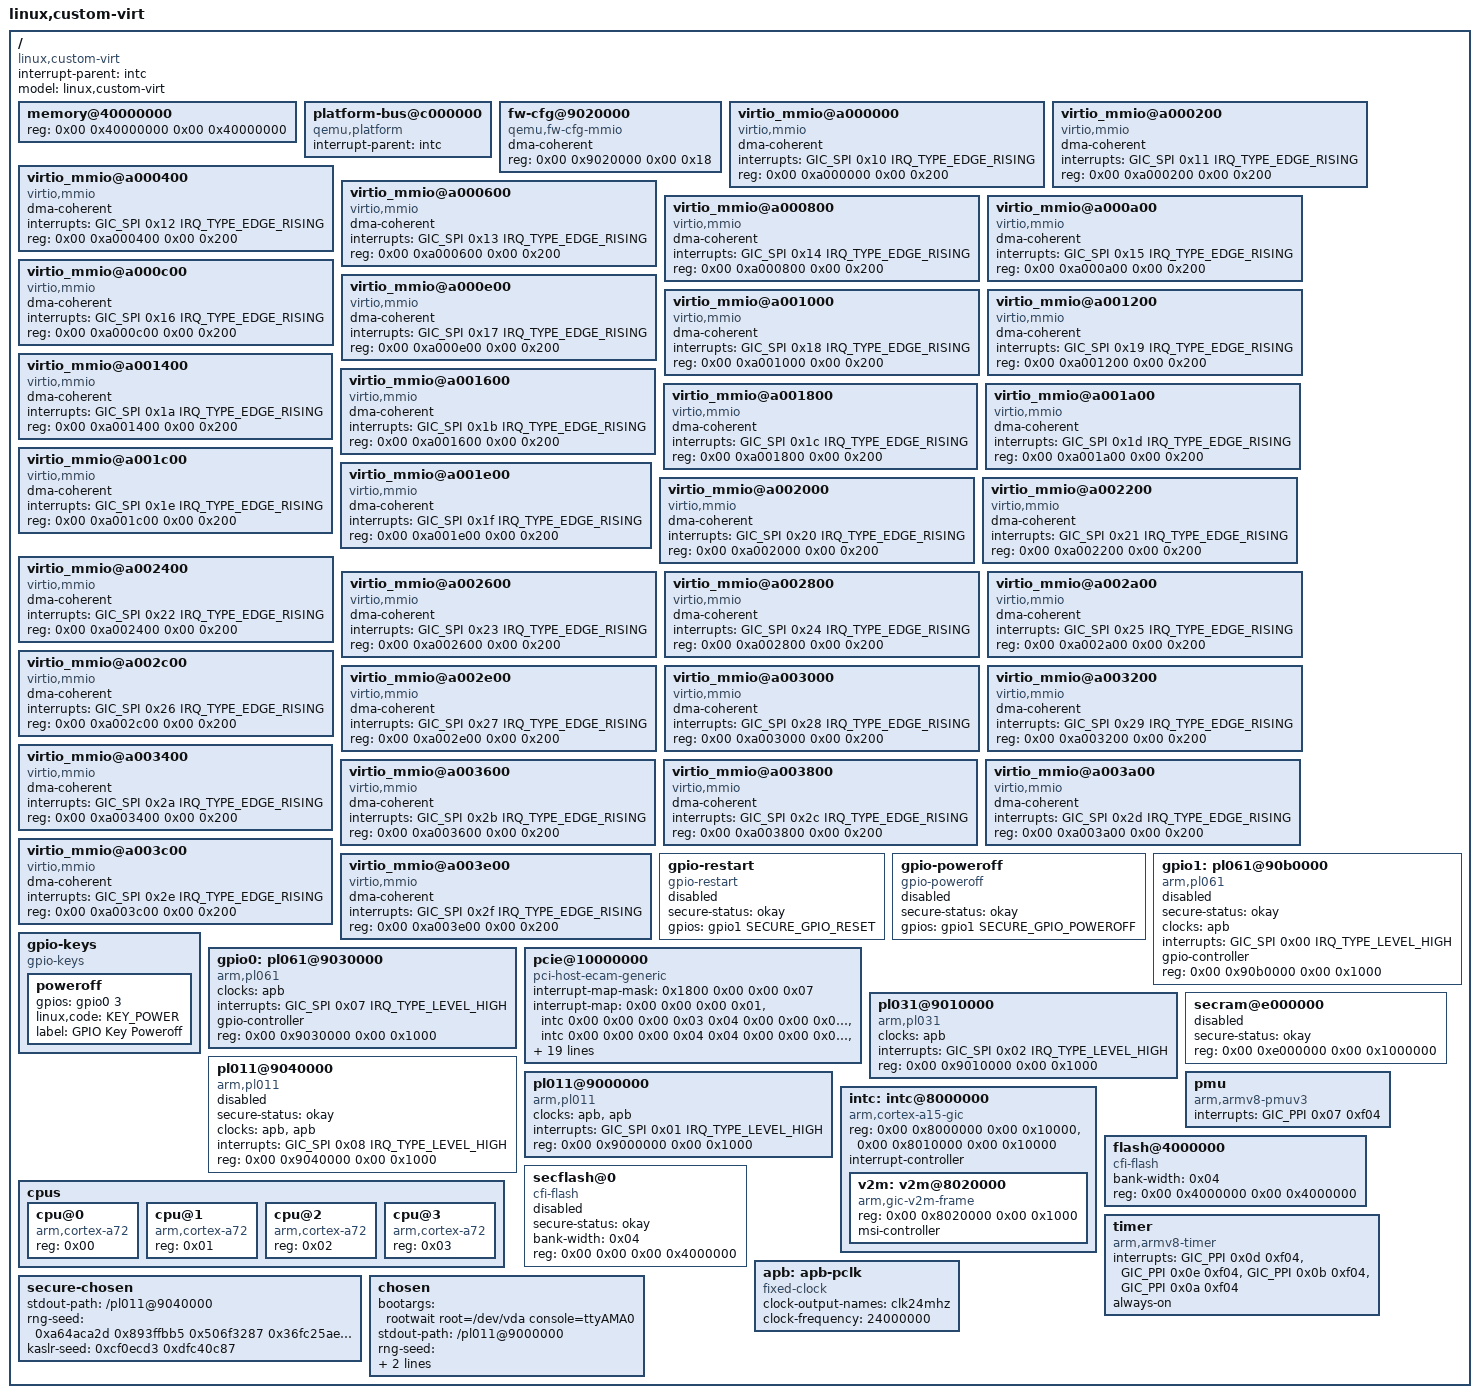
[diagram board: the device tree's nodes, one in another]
// SPDX-License-Identifier: GPL-2.0+
/dts-v1/;

#define SECURE_GPIO_POWEROFF 0
#define SECURE_GPIO_RESET    1

#define FDT_PCI_RANGE_RELOCATABLE          0x80000000
#define FDT_PCI_RANGE_PREFETCHABLE         0x40000000
#define FDT_PCI_RANGE_ALIASED              0x20000000
#define FDT_PCI_RANGE_TYPE_MASK            0x03000000
#define FDT_PCI_RANGE_MMIO_64BIT           0x03000000
#define FDT_PCI_RANGE_MMIO                 0x02000000
#define FDT_PCI_RANGE_IOPORT               0x01000000
#define FDT_PCI_RANGE_CONFIG               0x00000000

#include <dt-bindings/interrupt-controller/arm-gic.h>
#include <dt-bindings/input/linux-event-codes.h>

/ {
	interrupt-parent = <&intc>;
	model = "linux,custom-virt";
	#size-cells = <0x02>;
	#address-cells = <0x02>;
	compatible = "linux,custom-virt";

	memory@40000000 {
		reg = <0x00 0x40000000 0x00 0x40000000>;
		device_type = "memory";
	};

	platform-bus@c000000 {
		interrupt-parent = <&intc>;
		ranges = <0x00 0x00 0xc000000 0x2000000>;
		#address-cells = <0x01>;
		#size-cells = <0x01>;
		compatible = "qemu,platform", "simple-bus";
	};

	fw-cfg@9020000 {
		dma-coherent;
		reg = <0x00 0x9020000 0x00 0x18>;
		compatible = "qemu,fw-cfg-mmio";
	};

	virtio_mmio@a000000 {
		dma-coherent;
		interrupts = <GIC_SPI 0x10 IRQ_TYPE_EDGE_RISING>;
		reg = <0x00 0xa000000 0x00 0x200>;
		compatible = "virtio,mmio";
	};

	virtio_mmio@a000200 {
		dma-coherent;
		interrupts = <GIC_SPI 0x11 IRQ_TYPE_EDGE_RISING>;
		reg = <0x00 0xa000200 0x00 0x200>;
		compatible = "virtio,mmio";
	};

	virtio_mmio@a000400 {
		dma-coherent;
		interrupts = <GIC_SPI 0x12 IRQ_TYPE_EDGE_RISING>;
		reg = <0x00 0xa000400 0x00 0x200>;
		compatible = "virtio,mmio";
	};

	virtio_mmio@a000600 {
		dma-coherent;
		interrupts = <GIC_SPI 0x13 IRQ_TYPE_EDGE_RISING>;
		reg = <0x00 0xa000600 0x00 0x200>;
		compatible = "virtio,mmio";
	};

	virtio_mmio@a000800 {
		dma-coherent;
		interrupts = <GIC_SPI 0x14 IRQ_TYPE_EDGE_RISING>;
		reg = <0x00 0xa000800 0x00 0x200>;
		compatible = "virtio,mmio";
	};

	virtio_mmio@a000a00 {
		dma-coherent;
		interrupts = <GIC_SPI 0x15 IRQ_TYPE_EDGE_RISING>;
		reg = <0x00 0xa000a00 0x00 0x200>;
		compatible = "virtio,mmio";
	};

	virtio_mmio@a000c00 {
		dma-coherent;
		interrupts = <GIC_SPI 0x16 IRQ_TYPE_EDGE_RISING>;
		reg = <0x00 0xa000c00 0x00 0x200>;
		compatible = "virtio,mmio";
	};

	virtio_mmio@a000e00 {
		dma-coherent;
		interrupts = <GIC_SPI 0x17 IRQ_TYPE_EDGE_RISING>;
		reg = <0x00 0xa000e00 0x00 0x200>;
		compatible = "virtio,mmio";
	};

	virtio_mmio@a001000 {
		dma-coherent;
		interrupts = <GIC_SPI 0x18 IRQ_TYPE_EDGE_RISING>;
		reg = <0x00 0xa001000 0x00 0x200>;
		compatible = "virtio,mmio";
	};

	virtio_mmio@a001200 {
		dma-coherent;
		interrupts = <GIC_SPI 0x19 IRQ_TYPE_EDGE_RISING>;
		reg = <0x00 0xa001200 0x00 0x200>;
		compatible = "virtio,mmio";
	};

	virtio_mmio@a001400 {
		dma-coherent;
		interrupts = <GIC_SPI 0x1a IRQ_TYPE_EDGE_RISING>;
		reg = <0x00 0xa001400 0x00 0x200>;
		compatible = "virtio,mmio";
	};

	virtio_mmio@a001600 {
		dma-coherent;
		interrupts = <GIC_SPI 0x1b IRQ_TYPE_EDGE_RISING>;
		reg = <0x00 0xa001600 0x00 0x200>;
		compatible = "virtio,mmio";
	};

	virtio_mmio@a001800 {
		dma-coherent;
		interrupts = <GIC_SPI 0x1c IRQ_TYPE_EDGE_RISING>;
		reg = <0x00 0xa001800 0x00 0x200>;
		compatible = "virtio,mmio";
	};

	virtio_mmio@a001a00 {
		dma-coherent;
		interrupts = <GIC_SPI 0x1d IRQ_TYPE_EDGE_RISING>;
		reg = <0x00 0xa001a00 0x00 0x200>;
		compatible = "virtio,mmio";
	};

	virtio_mmio@a001c00 {
		dma-coherent;
		interrupts = <GIC_SPI 0x1e IRQ_TYPE_EDGE_RISING>;
		reg = <0x00 0xa001c00 0x00 0x200>;
		compatible = "virtio,mmio";
	};

	virtio_mmio@a001e00 {
		dma-coherent;
		interrupts = <GIC_SPI 0x1f IRQ_TYPE_EDGE_RISING>;
		reg = <0x00 0xa001e00 0x00 0x200>;
		compatible = "virtio,mmio";
	};

	virtio_mmio@a002000 {
		dma-coherent;
		interrupts = <GIC_SPI 0x20 IRQ_TYPE_EDGE_RISING>;
		reg = <0x00 0xa002000 0x00 0x200>;
		compatible = "virtio,mmio";
	};

	virtio_mmio@a002200 {
		dma-coherent;
		interrupts = <GIC_SPI 0x21 IRQ_TYPE_EDGE_RISING>;
		reg = <0x00 0xa002200 0x00 0x200>;
		compatible = "virtio,mmio";
	};

	virtio_mmio@a002400 {
		dma-coherent;
		interrupts = <GIC_SPI 0x22 IRQ_TYPE_EDGE_RISING>;
		reg = <0x00 0xa002400 0x00 0x200>;
		compatible = "virtio,mmio";
	};

	virtio_mmio@a002600 {
		dma-coherent;
		interrupts = <GIC_SPI 0x23 IRQ_TYPE_EDGE_RISING>;
		reg = <0x00 0xa002600 0x00 0x200>;
		compatible = "virtio,mmio";
	};

	virtio_mmio@a002800 {
		dma-coherent;
		interrupts = <GIC_SPI 0x24 IRQ_TYPE_EDGE_RISING>;
		reg = <0x00 0xa002800 0x00 0x200>;
		compatible = "virtio,mmio";
	};

	virtio_mmio@a002a00 {
		dma-coherent;
		interrupts = <GIC_SPI 0x25 IRQ_TYPE_EDGE_RISING>;
		reg = <0x00 0xa002a00 0x00 0x200>;
		compatible = "virtio,mmio";
	};

	virtio_mmio@a002c00 {
		dma-coherent;
		interrupts = <GIC_SPI 0x26 IRQ_TYPE_EDGE_RISING>;
		reg = <0x00 0xa002c00 0x00 0x200>;
		compatible = "virtio,mmio";
	};

	virtio_mmio@a002e00 {
		dma-coherent;
		interrupts = <GIC_SPI 0x27 IRQ_TYPE_EDGE_RISING>;
		reg = <0x00 0xa002e00 0x00 0x200>;
		compatible = "virtio,mmio";
	};

	virtio_mmio@a003000 {
		dma-coherent;
		interrupts = <GIC_SPI 0x28 IRQ_TYPE_EDGE_RISING>;
		reg = <0x00 0xa003000 0x00 0x200>;
		compatible = "virtio,mmio";
	};

	virtio_mmio@a003200 {
		dma-coherent;
		interrupts = <GIC_SPI 0x29 IRQ_TYPE_EDGE_RISING>;
		reg = <0x00 0xa003200 0x00 0x200>;
		compatible = "virtio,mmio";
	};

	virtio_mmio@a003400 {
		dma-coherent;
		interrupts = <GIC_SPI 0x2a IRQ_TYPE_EDGE_RISING>;
		reg = <0x00 0xa003400 0x00 0x200>;
		compatible = "virtio,mmio";
	};

	virtio_mmio@a003600 {
		dma-coherent;
		interrupts = <GIC_SPI 0x2b IRQ_TYPE_EDGE_RISING>;
		reg = <0x00 0xa003600 0x00 0x200>;
		compatible = "virtio,mmio";
	};

	virtio_mmio@a003800 {
		dma-coherent;
		interrupts = <GIC_SPI 0x2c IRQ_TYPE_EDGE_RISING>;
		reg = <0x00 0xa003800 0x00 0x200>;
		compatible = "virtio,mmio";
	};

	virtio_mmio@a003a00 {
		dma-coherent;
		interrupts = <GIC_SPI 0x2d IRQ_TYPE_EDGE_RISING>;
		reg = <0x00 0xa003a00 0x00 0x200>;
		compatible = "virtio,mmio";
	};

	virtio_mmio@a003c00 {
		dma-coherent;
		interrupts = <GIC_SPI 0x2e IRQ_TYPE_EDGE_RISING>;
		reg = <0x00 0xa003c00 0x00 0x200>;
		compatible = "virtio,mmio";
	};

	virtio_mmio@a003e00 {
		dma-coherent;
		interrupts = <GIC_SPI 0x2f IRQ_TYPE_EDGE_RISING>;
		reg = <0x00 0xa003e00 0x00 0x200>;
		compatible = "virtio,mmio";
	};

	gpio-restart {
		secure-status = "okay";
		status = "disabled";
		gpios = <&gpio1 SECURE_GPIO_RESET 0>;
		compatible = "gpio-restart";
	};

	gpio-poweroff {
		secure-status = "okay";
		status = "disabled";
		gpios = <&gpio1 SECURE_GPIO_POWEROFF 0>;
		compatible = "gpio-poweroff";
	};

	gpio1: pl061@90b0000 {
		secure-status = "okay";
		status = "disabled";
		clock-names = "apb_pclk";
		clocks = <&apb>;
		interrupts = <GIC_SPI 0x00 IRQ_TYPE_LEVEL_HIGH>;
		gpio-controller;
		#gpio-cells = <0x02>;
		compatible = "arm,pl061", "arm,primecell";
		reg = <0x00 0x90b0000 0x00 0x1000>;
	};

	gpio-keys {
		compatible = "gpio-keys";

		poweroff {
			gpios = <&gpio0 3 0>;
			linux,code = <KEY_POWER>;
			label = "GPIO Key Poweroff";
		};
	};

	gpio0: pl061@9030000 {
		clock-names = "apb_pclk";
		clocks = <&apb>;
		interrupts = <GIC_SPI 0x07 IRQ_TYPE_LEVEL_HIGH>;
		gpio-controller;
		#gpio-cells = <0x02>;
		compatible = "arm,pl061", "arm,primecell";
		reg = <0x00 0x9030000 0x00 0x1000>;
	};

	pcie@10000000 {
		interrupt-map-mask = <0x1800 0x00 0x00 0x07>;
		interrupt-map = <0x00 0x00 0x00 0x01 &intc 0x00 0x00 0x00 0x03 0x04 0x00 0x00 0x00 0x02 &intc 0x00 0x00 0x00 0x04 0x04 0x00 0x00 0x00 0x03 &intc 0x00 0x00 0x00 0x05 0x04 0x00 0x00 0x00 0x04 &intc 0x00 0x00 0x00 0x06 0x04 0x800 0x00 0x00 0x01 &intc 0x00 0x00 0x00 0x04 0x04 0x800 0x00 0x00 0x02 &intc 0x00 0x00 0x00 0x05 0x04 0x800 0x00 0x00 0x03 &intc 0x00 0x00 0x00 0x06 0x04 0x800 0x00 0x00 0x04 &intc 0x00 0x00 0x00 0x03 0x04 0x1000 0x00 0x00 0x01 &intc 0x00 0x00 0x00 0x05 0x04 0x1000 0x00 0x00 0x02 &intc 0x00 0x00 0x00 0x06 0x04 0x1000 0x00 0x00 0x03 &intc 0x00 0x00 0x00 0x03 0x04 0x1000 0x00 0x00 0x04 &intc 0x00 0x00 0x00 0x04 0x04 0x1800 0x00 0x00 0x01 &intc 0x00 0x00 0x00 0x06 0x04 0x1800 0x00 0x00 0x02 &intc 0x00 0x00 0x00 0x03 0x04 0x1800 0x00 0x00 0x03 &intc 0x00 0x00 0x00 0x04 0x04 0x1800 0x00 0x00 0x04 &intc 0x00 0x00 0x00 0x05 0x04>;
		#interrupt-cells = <0x01>;
		ranges =	<FDT_PCI_RANGE_IOPORT 0x00 0x00>, 
					<0x00 0x3eff0000 0x00 0x10000>, 
					<FDT_PCI_RANGE_MMIO 0x00 0x10000000>, 
					<0x00 0x10000000 0x00 0x2eff0000>, 
					<FDT_PCI_RANGE_MMIO_64BIT>, 
					<0x80 0x00>, 
					<0x80 0x00 0x80 0x00>;
		reg = <0x40 0x10000000 0x00 0x10000000>;
		msi-map = <0x00 0x8006 0x00 0x10000>;
		dma-coherent;
		bus-range = <0x00 0xff>;
		linux,pci-domain = <0x00>;
		#size-cells = <0x02>;
		#address-cells = <0x03>;
		device_type = "pci";
		compatible = "pci-host-ecam-generic";
	};

	pl031@9010000 {
		clock-names = "apb_pclk";
		clocks = <&apb>;
		interrupts = <GIC_SPI 0x02 IRQ_TYPE_LEVEL_HIGH>;
		reg = <0x00 0x9010000 0x00 0x1000>;
		compatible = "arm,pl031", "arm,primecell";
	};

	pl011@9040000 {
		secure-status = "okay";
		status = "disabled";
		clock-names = "uartclk", "apb_pclk";
		clocks = <&apb &apb>;
		interrupts = <GIC_SPI 0x08 IRQ_TYPE_LEVEL_HIGH>;
		reg = <0x00 0x9040000 0x00 0x1000>;
		compatible = "arm,pl011", "arm,primecell";
	};

	secram@e000000 {
		secure-status = "okay";
		status = "disabled";
		reg = <0x00 0xe000000 0x00 0x1000000>;
		device_type = "memory";
	};

	pl011@9000000 {
		clock-names = "uartclk", "apb_pclk";
		clocks = <&apb &apb>;
		interrupts = <GIC_SPI 0x01 IRQ_TYPE_LEVEL_HIGH>;
		reg = <0x00 0x9000000 0x00 0x1000>;
		compatible = "arm,pl011", "arm,primecell";
	};

	pmu {
		interrupts = <GIC_PPI 0x07 0xf04>;
		compatible = "arm,armv8-pmuv3";
	};

	intc: intc@8000000 {
		reg = <0x00 0x8000000 0x00 0x10000>, <0x00 0x8010000 0x00 0x10000>;
		compatible = "arm,cortex-a15-gic";
		ranges;
		#size-cells = <0x02>;
		#address-cells = <0x02>;
		interrupt-controller;
		#interrupt-cells = <0x03>;

		v2m: v2m@8020000 {
			// phandle = <0x8006>;
			reg = <0x00 0x8020000 0x00 0x1000>;
			msi-controller;
			compatible = "arm,gic-v2m-frame";
		};
	};

	flash@4000000 {
		bank-width = <0x04>;
		reg = <0x00 0x4000000 0x00 0x4000000>;
		compatible = "cfi-flash";
	};

	secflash@0 {
		secure-status = "okay";
		status = "disabled";
		bank-width = <0x04>;
		reg = <0x00 0x00 0x00 0x4000000>;
		compatible = "cfi-flash";
	};

	cpus {
		#size-cells = <0x00>;
		#address-cells = <0x01>;
		cpu@0 {
			reg = <0x00>;
			compatible = "arm,cortex-a72";
			device_type = "cpu";
		};

		cpu@1 {
			reg = <0x01>;
			compatible = "arm,cortex-a72";
			device_type = "cpu";
		};

		cpu@2 {
			reg = <0x02>;
			compatible = "arm,cortex-a72";
			device_type = "cpu";
		};

		cpu@3 {
			reg = <0x03>;
			compatible = "arm,cortex-a72";
			device_type = "cpu";
		};
	};

	timer {
		interrupts = 	<GIC_PPI 0x0d 0xf04>, 
						<GIC_PPI 0x0e 0xf04>, 
						<GIC_PPI 0x0b 0xf04>, 
						<GIC_PPI 0x0a 0xf04>;
		always-on;
		compatible = "arm,armv8-timer", "arm,armv7-timer";
	};

	apb: apb-pclk {
		clock-output-names = "clk24mhz";
		clock-frequency = <24000000>;
		#clock-cells = <0x00>;
		compatible = "fixed-clock";
	};

	secure-chosen {
		stdout-path = "/pl011@9040000";
		rng-seed = <0xa64aca2d 0x893ffbb5 0x506f3287 0x36fc25ae 0xa2e5010f 0xcadc6c67 0x72e6ecdf 0x250bf623>;
		kaslr-seed = <0xcf0ecd3 0xdfc40c87>;
	};

	chosen {
		bootargs = "rootwait root=/dev/vda console=ttyAMA0";
		stdout-path = "/pl011@9000000";
		rng-seed = <0x16edca74 0x4c3e0aaa 0xedefd4b2 0x4277709c 0x7df2cc81 0x2f1447f0 0x32b4e75a 0x1615037f>;
		kaslr-seed = <0x92e4bf75 0x27f56195>;
	};
};
